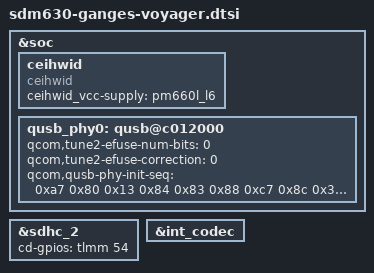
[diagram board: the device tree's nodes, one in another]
/* arch/arm64/boot/dts/somc/sdm630-ganges-voyager.dtsi
 *
 * This program is free software; you can redistribute it and/or modify
 * it under the terms of the GNU General Public License version 2 and
 * only version 2 as published by the Free Software Foundation.
 *
 * This program is distributed in the hope that it will be useful,
 * but WITHOUT ANY WARRANTY; without even the implied warranty of
 * MERCHANTABILITY or FITNESS FOR A PARTICULAR PURPOSE.  See the
 * GNU General Public License for more details.
*/

#include "sdm630-ganges-common.dtsi"
#include "display/dsi-panel-voyager.dtsi"
#include "sdm630-ganges-touch.dtsi"
#include "camera/sdm630-ganges-voyager-camera-sensor.dtsi"
#include "battery/charger-ganges-voyager.dtsi"

&soc {
	ceihwid {
		compatible = "ceihwid";
		ceihwid_vcc-supply = <&pm660l_l6>;
	};

	qusb_phy0: qusb@c012000 {
		qcom,tune2-efuse-num-bits = <0>;
		qcom,tune2-efuse-correction = <0>;
		qcom,qusb-phy-init-seq = <0xa7 0x80
			0x13 0x84
			0x83 0x88
			0xc7 0x8c
			0x30 0x08
			0x79 0x0c
			0x21 0x10
			0x14 0x9c
			0x9f 0x1c
			0x00 0x18>;
	};
};

&sdhc_2 {
	cd-gpios = <&tlmm 54 0x0>;
};

&int_codec {
	/delete-property/ qcom,msm-micbias2-ext-cap;
};
